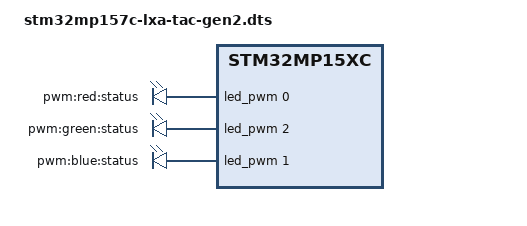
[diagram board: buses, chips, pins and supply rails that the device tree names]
// SPDX-License-Identifier: (GPL-2.0+ OR BSD-3-Clause)
/*
 * Copyright (C) 2023 Leonard Göhrs, Pengutronix
 */

#include <arm/st/stm32mp157c-lxa-tac-gen2.dts>
#include "stm32mp15xc-lxa-tac.dtsi"

/ {
	led-controller-pwm {
		compatible = "pwm-leds";

		led-status-red {
			label = "pwm:red:status";
			pwms = <&led_pwm 0 1000000 0>;
			active-low;
			max-brightness = <255>;
		};

		led-status-green {
			label = "pwm:green:status";
			pwms = <&led_pwm 2 1000000 0>;
			active-low;
			max-brightness = <255>;
		};

		led-status-blue {
			label = "pwm:blue:status";
			pwms = <&led_pwm 1 1000000 0>;
			active-low;
			max-brightness = <255>;
		};
	};

	led-controller-1 {
		status = "disabled";
	};
};
